# RP2350 register map
Vendor: Raspberry Pi; File version: 0.1
CPU: CM33 r1p0, little endian, MPU, FPU, VTOR, 4 interrupt priority bits, 54 interrupts, 8 SAU regions
Registers are 32-bit, read-write, reset 0x0 unless marked. A register's access mark holds for its fields unless they carry their own. Offsets are from the block's base; [hi:lo] are bit positions; {n}, {i} and the like mark numbered series; 'fields as' and 'values as' point back to an identical list; <NAME> marks a mode.

## OTP_DATA — Predefined OTP data layout for RP2350
Base 0x40130000
0x00 CHIPID_DEVICE0 ro — Lower 16 bits of test lot/device number (ECC)
  [15:0] CHIPID_DEVICE0
0x01 CHIPID_DEVICE1 ro — Upper 16 bits of test lot/device number (ECC)
  [15:0] CHIPID_DEVICE1
0x02 CHIPID_WAFER0 ro — Lower 16 bits of wafer lot (ECC)
  [15:0] CHIPID_WAFER0
0x03 CHIPID_WAFER1 ro — Upper 16 bits of wafer lot (ECC)
  [15:0] CHIPID_WAFER1
{0x4+i} RANDID{i} ro (i=0..7) — 16 bits of random data sampled from the TRNG during manufacturing (ECC)
  [15:0] RANDID{i}
0x10 ROSC_CALIB ro — Ring oscillator calibration constant measured during manufacturing (ECC)
  [15:0] ROSC_CALIB
0x11 LPOSC_CALIB ro — Low-power oscillator calibration constant measured during manufacturing (ECC)
  [15:0] LPOSC_CALIB
0x36 INFO_CRC0 ro — Lower 16 bits of CRC32 of OTP addresses 0x00 through 0x6b (polynomial 0x4c11db7, input reflected, output reflected, seed all-ones, final XOR all-ones) (ECC)
  [15:0] INFO_CRC0
0x37 INFO_CRC1 ro — Upper 16 bits of CRC32 of OTP addresses 0x00 through 0x6b (ECC)
  [15:0] INFO_CRC1
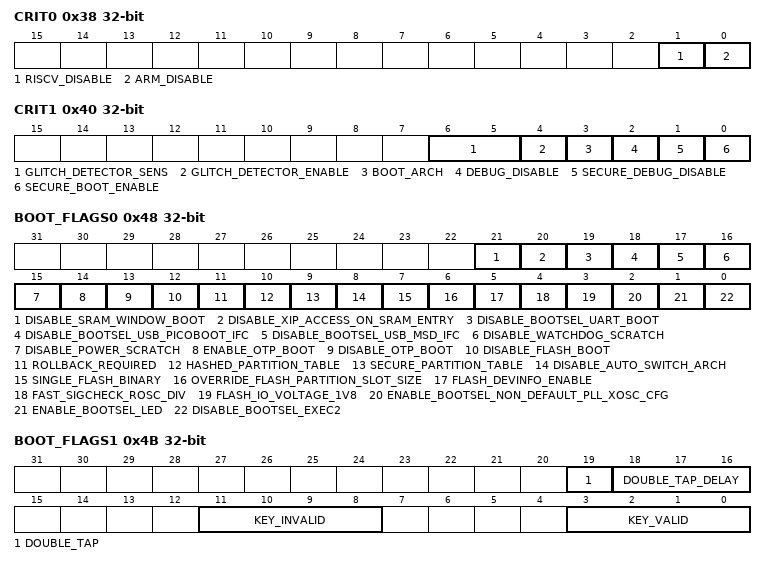
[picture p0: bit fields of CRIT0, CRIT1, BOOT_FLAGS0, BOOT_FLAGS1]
0x38 CRIT0 ro — Page 0 critical boot flags (RBIT-8)
  [1] RISCV_DISABLE — Permanently disable RISC-V processors (Hazard3)
  [0] ARM_DISABLE — Permanently disable ARM processors (Cortex-M33)
{0x38+i} CRIT0_R{i} ro (i=1..7) — Redundant copy of CRIT0
  [23:0] CRIT0_R{i}
0x40 CRIT1 ro — Page 1 critical boot flags (RBIT-8)
  [6:5] GLITCH_DETECTOR_SENS — Increase the sensitivity of the glitch detectors from their default.
  [4] GLITCH_DETECTOR_ENABLE — Arm the glitch detectors to reset the system if an abnormal clock/power event is observed.
  [3] BOOT_ARCH — Set the default boot architecture, 0=ARM 1=RISC-V. Ignored if ARM_DISABLE, RISCV_DISABLE or SECURE_BOOT_ENABLE is set.
  [2] DEBUG_DISABLE — Disable all debug access
  [1] SECURE_DEBUG_DISABLE — Disable Secure debug access
  [0] SECURE_BOOT_ENABLE — Enable boot signature enforcement, and permanently disable the RISC-V cores.
{0x40+i} CRIT1_R{i} ro (i=1..7) — Redundant copy of CRIT1
  [23:0] CRIT1_R{i}
0x48 BOOT_FLAGS0 ro — Disable/Enable boot paths/features in the RP2350 mask ROM. Disables always supersede enables. Enables are provided where there are other configurations in OTP that must be valid. (RBIT-3)
  [21] DISABLE_SRAM_WINDOW_BOOT
  [20] DISABLE_XIP_ACCESS_ON_SRAM_ENTRY
  [19] DISABLE_BOOTSEL_UART_BOOT
  [18] DISABLE_BOOTSEL_USB_PICOBOOT_IFC
  [17] DISABLE_BOOTSEL_USB_MSD_IFC
  [16] DISABLE_WATCHDOG_SCRATCH
  [15] DISABLE_POWER_SCRATCH
  [14] ENABLE_OTP_BOOT — Enable OTP boot. A number of OTP rows specified by OTPBOOT_LEN will be loaded, starting from OTPBOOT_SRC, into the SRAM location specified by OTPBOOT_DST1 and OTPBOOT_DST0. . The loaded program image is stored with ECC, 16 bits per row, and must contain a valid IMAGE_DEF. Do not set this bit without first programming an image into OTP and configuring OTPBOOT_LEN, OTPBOOT_SRC, OTPBOOT_DST0 and OTPBOOT_DST1. . Note that OTPBOOT_LEN and OTPBOOT_SRC must be even numbers of OTP rows. Equivalently, the image must be a multiple of 32 bits in size, and must start at a 32-bit-aligned address in the ECC read data address window.
  [13] DISABLE_OTP_BOOT — Takes precedence over ENABLE_OTP_BOOT.
  [12] DISABLE_FLASH_BOOT
  [11] ROLLBACK_REQUIRED — Require binaries to have a rollback version. Set automatically the first time a binary with a rollback version is booted.
  [10] HASHED_PARTITION_TABLE — Require a partition table to be hashed (if not signed)
  [9] SECURE_PARTITION_TABLE — Require a partition table to be signed
  [8] DISABLE_AUTO_SWITCH_ARCH — Disable auto-switch of CPU architecture on boot when the (only) binary to be booted is for the other Arm/RISC-V architecture and both architectures are enabled
  [7] SINGLE_FLASH_BINARY — Restrict flash boot path to use of a single binary at the start of flash
  [6] OVERRIDE_FLASH_PARTITION_SLOT_SIZE — Override the limit for default flash metadata scanning. . The value is specified in FLASH_PARTITION_SLOT_SIZE. Make sure FLASH_PARTITION_SLOT_SIZE is valid before setting this bit
  [5] FLASH_DEVINFO_ENABLE — Mark FLASH_DEVINFO as containing valid, ECC'd data which describes external flash devices.
  [4] FAST_SIGCHECK_ROSC_DIV — Enable quartering of ROSC divisor during signature check, to reduce secure boot time
  [3] FLASH_IO_VOLTAGE_1V8 — If 1, configure the QSPI pads for 1.8 V operation when accessing flash for the first time from the bootrom, using the VOLTAGE_SELECT register for the QSPI pads bank. This slightly improves the input timing of the pads at low voltages, but does not affect their output characteristics. . If 0, leave VOLTAGE_SELECT in its reset state (suitable for operation at and above 2.5 V)
  [2] ENABLE_BOOTSEL_NON_DEFAULT_PLL_XOSC_CFG — Enable loading of the non-default XOSC and PLL configuration before entering BOOTSEL mode. . Ensure that BOOTSEL_XOSC_CFG and BOOTSEL_PLL_CFG are correctly programmed before setting this bit. . If this bit is set, user software may use the contents of BOOTSEL_PLL_CFG to calculated the expected XOSC frequency based on the fixed USB boot frequency of 48 MHz.
  [1] ENABLE_BOOTSEL_LED — Enable bootloader activity LED. If set, bootsel_led_cfg is assumed to be valid
  [0] DISABLE_BOOTSEL_EXEC2
0x49 BOOT_FLAGS0_R1 ro — Redundant copy of BOOT_FLAGS0
  [23:0] BOOT_FLAGS0_R1
0x4A BOOT_FLAGS0_R2 ro — Redundant copy of BOOT_FLAGS0
  [23:0] BOOT_FLAGS0_R2
0x4B BOOT_FLAGS1 ro — Disable/Enable boot paths/features in the RP2350 mask ROM. Disables always supersede enables. Enables are provided where there are other configurations in OTP that must be valid. (RBIT-3)
  [19] DOUBLE_TAP — Enable entering BOOTSEL mode via double-tap of the RUN/RSTn pin. Adds a significant delay to boot time, as configured by DOUBLE_TAP_DELAY. . This functions by waiting at startup (i.e. following a reset) to see if a second reset is applied soon afterward. The second reset is detected by the bootrom with help of the POWMAN_CHIP_RESET_DOUBLE_TAP flag, which is not reset by the external reset pin, and the bootrom enters BOOTSEL mode (NSBOOT) to await further instruction over USB or UART.
  [18:16] DOUBLE_TAP_DELAY — Adjust how long to wait for a second reset when double tap BOOTSEL mode is enabled via DOUBLE_TAP. The minimum is 50 milliseconds, and each unit of this field adds an additional 50 milliseconds. . For example, settings this field to its maximum value of 7 will cause the chip to wait for 400 milliseconds at boot to check for a second reset which requests entry to BOOTSEL mode. . 200 milliseconds (DOUBLE_TAP_DELAY=3) is a good intermediate value.
  [11:8] KEY_INVALID — Mark a boot key as invalid, or prevent it from ever becoming valid. The bootrom will ignore any boot key marked as invalid during secure boot signature checks. . Each bit in this field corresponds to one of the four 256-bit boot key hashes that may be stored in page 2 of the OTP. . When provisioning boot keys, it's recommended to mark any boot key slots you don't intend to use as KEY_INVALID, so that spurious keys can not be installed at a later time.
  [3:0] KEY_VALID — Mark each of the possible boot keys as valid. The bootrom will check signatures against all valid boot keys, and ignore invalid boot keys. . Each bit in this field corresponds to one of the four 256-bit boot key hashes that may be stored in page 2 of the OTP. . A KEY_VALID bit is ignored if the corresponding KEY_INVALID bit is set. Boot keys are considered valid only when KEY_VALID is set and KEY_INVALID is clear. . Do not mark a boot key as KEY_VALID if it does not contain a valid SHA-256 hash of your secp256k1 public key. Verify keys after programming, before setting the KEY_VALID bits -- a boot key with uncorrectable ECC faults will render your device unbootable if secure boot is enabled. . Do not enable secure boot without first installing a valid key. This will render your device unbootable.
0x4C BOOT_FLAGS1_R1 ro — Redundant copy of BOOT_FLAGS1
  [23:0] BOOT_FLAGS1_R1
0x4D BOOT_FLAGS1_R2 ro — Redundant copy of BOOT_FLAGS1
  [23:0] BOOT_FLAGS1_R2
0x4E DEFAULT_BOOT_VERSION0 ro — Default boot version thermometer counter, bits 23:0 (RBIT-3)
  [23:0] DEFAULT_BOOT_VERSION0
0x4F DEFAULT_BOOT_VERSION0_R1 ro — Redundant copy of DEFAULT_BOOT_VERSION0
  [23:0] DEFAULT_BOOT_VERSION0_R1
0x50 DEFAULT_BOOT_VERSION0_R2 ro — Redundant copy of DEFAULT_BOOT_VERSION0
  [23:0] DEFAULT_BOOT_VERSION0_R2
0x51 DEFAULT_BOOT_VERSION1 ro — Default boot version thermometer counter, bits 47:24 (RBIT-3)
  [23:0] DEFAULT_BOOT_VERSION1
0x52 DEFAULT_BOOT_VERSION1_R1 ro — Redundant copy of DEFAULT_BOOT_VERSION1
  [23:0] DEFAULT_BOOT_VERSION1_R1
0x53 DEFAULT_BOOT_VERSION1_R2 ro — Redundant copy of DEFAULT_BOOT_VERSION1
  [23:0] DEFAULT_BOOT_VERSION1_R2
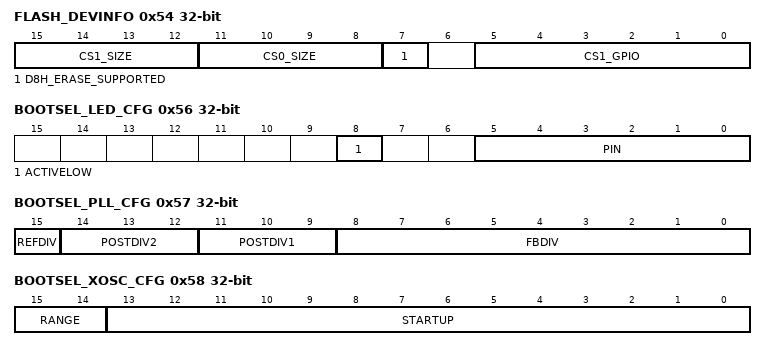
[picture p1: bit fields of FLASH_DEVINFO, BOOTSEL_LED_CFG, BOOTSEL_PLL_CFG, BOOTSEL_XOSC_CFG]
0x54 FLASH_DEVINFO ro — Stores information about external flash device(s). (ECC) . Assumed to be valid if BOOT_FLAGS0_FLASH_DEVINFO_ENABLE is set.
  [15:12] CS1_SIZE — The size of the flash/PSRAM device on chip select 1 (addressable at 0x11000000 through 0x11ffffff). . A value of zero is decoded as a size of zero (no device). Nonzero values are decoded as 4kiB << CS1_SIZE. For example, four megabytes is encoded with a CS1_SIZE value of 10, and 16 megabytes is encoded with a CS1_SIZE value of 12. . When BOOT_FLAGS0_FLASH_DEVINFO_ENABLE is not set, a default of zero is used.
    0=NONE; 1=8K; 2=16K; 3=32K; 4=64k; 5=128K; 6=256K; 7=512K; 8=1M; 9=2M; 10=4M; 11=8M; 12=16M
  [11:8] CS0_SIZE — The size of the flash/PSRAM device on chip select 0 (addressable at 0x10000000 through 0x10ffffff). . A value of zero is decoded as a size of zero (no device). Nonzero values are decoded as 4kiB << CS0_SIZE. For example, four megabytes is encoded with a CS0_SIZE value of 10, and 16 megabytes is encoded with a CS0_SIZE value of 12. . When BOOT_FLAGS0_FLASH_DEVINFO_ENABLE is not set, a default of 12 (16 MiB) is used.
    values as CS1_SIZE
  [7] D8H_ERASE_SUPPORTED — If true, all attached devices are assumed to support (or ignore, in the case of PSRAM) a block erase command with a command prefix of D8h, an erase size of 64 kiB, and a 24-bit address. Almost all 25-series flash devices support this command. . If set, the bootrom will use the D8h erase command where it is able, to accelerate bulk erase operations. This makes flash programming faster. . When BOOT_FLAGS0_FLASH_DEVINFO_ENABLE is not set, this field defaults to false.
  [5:0] CS1_GPIO — Indicate a GPIO number to be used for the secondary flash chip select (CS1), which selects the external QSPI device mapped at system addresses 0x11000000 through 0x11ffffff. There is no such configuration for CS0, as the primary chip select has a dedicated pin. . On RP2350 the permissible GPIO numbers are 0, 8, 19 and 47. . Ignored if CS1_size is zero. If CS1_SIZE is nonzero, the bootrom will automatically configure this GPIO as a second chip select upon entering the flash boot path, or entering any other path that may use the QSPI flash interface, such as BOOTSEL mode (nsboot).
0x55 FLASH_PARTITION_SLOT_SIZE ro — Gap between partition table slot 0 and slot 1 at the start of flash (the default size is 4096 bytes) (ECC) Enabled by the OVERRIDE_FLASH_PARTITION_SLOT_SIZE bit in BOOT_FLAGS, the size is 4096 * (value + 1)
  [15:0] FLASH_PARTITION_SLOT_SIZE
0x56 BOOTSEL_LED_CFG ro — Pin configuration for LED status, used by USB bootloader. (ECC). Must be valid if BOOT_FLAGS0_ENABLE_BOOTSEL_LED is set.
  [8] ACTIVELOW — LED is active-low. (Default: active-high.)
  [5:0] PIN — GPIO index to use for bootloader activity LED.
0x57 BOOTSEL_PLL_CFG ro — Optional PLL configuration for BOOTSEL mode. (ECC) . This should be configured to produce an exact 48 MHz based on the crystal oscillator frequency. User mode software may also use this value to calculate the expected crystal frequency based on an assumed 48 MHz PLL output. . If no configuration is given, the crystal is assumed to be 12 MHz. . The PLL frequency can be calculated as: . PLL out = (XOSC frequency / (REFDIV+1)) x FBDIV / (POSTDIV1 x POSTDIV2) . Conversely the crystal frequency can be calculated as: . XOSC frequency = 48 MHz x (REFDIV+1) x (POSTDIV1 x POSTDIV2) / FBDIV (Note the +1 on REFDIV is because the value stored in this OTP location is the actual divisor value minus one.) . Valid if and only if BOOTSEL_CFG_NONDEFAULT_CLOCK_CFG bit is set. That bit should be set only after this row and BOOTSEL_XOSC_CFG are both correctly programmed.
  [15] REFDIV — PLL reference divisor, minus one. . Programming a value of 0 means a reference divisor of 1. Programming a value of 1 means a reference divisor of 2 (for exceptionally fast XIN inputs)
  [14:12] POSTDIV2 — PLL post-divide 2 divisor, in the range 1..7 inclusive.
  [11:9] POSTDIV1 — PLL post-divide 1 divisor, in the range 1..7 inclusive.
  [8:0] FBDIV — PLL feedback divisor, in the range 16..320 inclusive.
0x58 BOOTSEL_XOSC_CFG ro — Non-default crystal oscillator configuration for the USB bootloader. (ECC) . These values may also be used by user code configuring the crystal oscillator. . Valid if and only if BOOTSEL_CFG_NONDEFAULT_CLOCK_CFG bit is set. That bit should be set only after this row and BOOTSEL_PLL_CFG are both correctly programmed.
  [15:14] RANGE — Value of the XOSC_CTRL_FREQ_RANGE register.
    0=1_15MHZ; 1=10_30MHZ; 2=25_60MHZ; 3=40_100MHZ
  [13:0] STARTUP — Value of the XOSC_STARTUP register
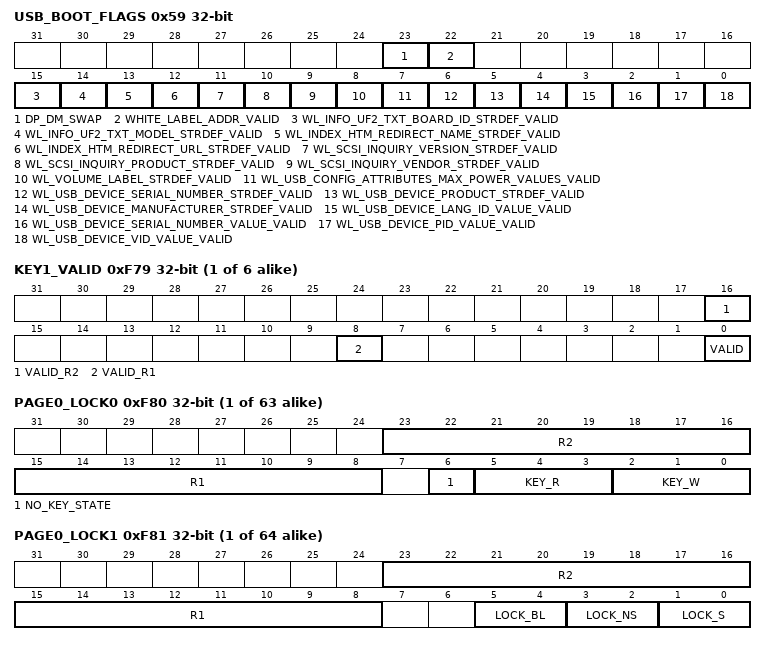
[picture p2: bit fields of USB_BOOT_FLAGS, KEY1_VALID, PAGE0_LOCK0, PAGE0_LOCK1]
0x59 USB_BOOT_FLAGS ro — USB boot specific feature flags (RBIT-3)
  [23] DP_DM_SWAP — Swap DM/DP during USB boot, to support board layouts with mirrored USB routing (deliberate or accidental).
  [22] WHITE_LABEL_ADDR_VALID — valid flag for INFO_UF2_TXT_BOARD_ID_STRDEF entry of the USB_WHITE_LABEL struct (index 15)
  [15] WL_INFO_UF2_TXT_BOARD_ID_STRDEF_VALID — valid flag for the USB_WHITE_LABEL_ADDR field
  [14] WL_INFO_UF2_TXT_MODEL_STRDEF_VALID — valid flag for INFO_UF2_TXT_MODEL_STRDEF entry of the USB_WHITE_LABEL struct (index 14)
  [13] WL_INDEX_HTM_REDIRECT_NAME_STRDEF_VALID — valid flag for INDEX_HTM_REDIRECT_NAME_STRDEF entry of the USB_WHITE_LABEL struct (index 13)
  [12] WL_INDEX_HTM_REDIRECT_URL_STRDEF_VALID — valid flag for INDEX_HTM_REDIRECT_URL_STRDEF entry of the USB_WHITE_LABEL struct (index 12)
  [11] WL_SCSI_INQUIRY_VERSION_STRDEF_VALID — valid flag for SCSI_INQUIRY_VERSION_STRDEF entry of the USB_WHITE_LABEL struct (index 11)
  [10] WL_SCSI_INQUIRY_PRODUCT_STRDEF_VALID — valid flag for SCSI_INQUIRY_PRODUCT_STRDEF entry of the USB_WHITE_LABEL struct (index 10)
  [9] WL_SCSI_INQUIRY_VENDOR_STRDEF_VALID — valid flag for SCSI_INQUIRY_VENDOR_STRDEF entry of the USB_WHITE_LABEL struct (index 9)
  [8] WL_VOLUME_LABEL_STRDEF_VALID — valid flag for VOLUME_LABEL_STRDEF entry of the USB_WHITE_LABEL struct (index 8)
  [7] WL_USB_CONFIG_ATTRIBUTES_MAX_POWER_VALUES_VALID — valid flag for USB_CONFIG_ATTRIBUTES_MAX_POWER_VALUES entry of the USB_WHITE_LABEL struct (index 7)
  [6] WL_USB_DEVICE_SERIAL_NUMBER_STRDEF_VALID — valid flag for USB_DEVICE_SERIAL_NUMBER_STRDEF entry of the USB_WHITE_LABEL struct (index 6)
  [5] WL_USB_DEVICE_PRODUCT_STRDEF_VALID — valid flag for USB_DEVICE_PRODUCT_STRDEF entry of the USB_WHITE_LABEL struct (index 5)
  [4] WL_USB_DEVICE_MANUFACTURER_STRDEF_VALID — valid flag for USB_DEVICE_MANUFACTURER_STRDEF entry of the USB_WHITE_LABEL struct (index 4)
  [3] WL_USB_DEVICE_LANG_ID_VALUE_VALID — valid flag for USB_DEVICE_LANG_ID_VALUE entry of the USB_WHITE_LABEL struct (index 3)
  [2] WL_USB_DEVICE_SERIAL_NUMBER_VALUE_VALID — valid flag for USB_DEVICE_BCD_DEVICEVALUE entry of the USB_WHITE_LABEL struct (index 2)
  [1] WL_USB_DEVICE_PID_VALUE_VALID — valid flag for USB_DEVICE_PID_VALUE entry of the USB_WHITE_LABEL struct (index 1)
  [0] WL_USB_DEVICE_VID_VALUE_VALID — valid flag for USB_DEVICE_VID_VALUE entry of the USB_WHITE_LABEL struct (index 0)
0x5A USB_BOOT_FLAGS_R1 ro — Redundant copy of USB_BOOT_FLAGS
  [23:0] USB_BOOT_FLAGS_R1
0x5B USB_BOOT_FLAGS_R2 ro — Redundant copy of USB_BOOT_FLAGS
  [23:0] USB_BOOT_FLAGS_R2
0x5C USB_WHITE_LABEL_ADDR ro — Row index of the USB_WHITE_LABEL structure within OTP (ECC) . The table has 16 rows, each of which are also ECC and marked valid by the corresponding valid bit in USB_BOOT_FLAGS (ECC). . The entries are either _VALUEs where the 16 bit value is used as is, or _STRDEFs which acts as a pointers to a string value. . The value stored in a _STRDEF is two separate bytes: The low seven bits of the first (LSB) byte indicates the number of characters in the string, and the top bit of the first (LSB) byte if set to indicate that each character in the string is two bytes (Unicode) versus one byte if unset. The second (MSB) byte represents the location of the string data, and is encoded as the number of rows from this USB_WHITE_LABEL_ADDR; i.e. the row of the start of the string is USB_WHITE_LABEL_ADDR value + msb_byte. . In each case, the corresponding valid bit enables replacing the default value for the corresponding item provided by the boot rom. . Note that Unicode _STRDEFs are only supported for USB_DEVICE_PRODUCT_STRDEF, USB_DEVICE_SERIAL_NUMBER_STRDEF and USB_DEVICE_MANUFACTURER_STRDEF. Unicode values will be ignored if specified for other fields, and non-unicode values for these three items will be converted to Unicode characters by setting the upper 8 bits to zero. . Note that if the USB_WHITE_LABEL structure or the corresponding strings are not readable by BOOTSEL mode based on OTP permissions, or if alignment requirements are not met, then the corresponding default values are used. . The index values indicate where each field is located (row USB_WHITE_LABEL_ADDR value + index):
  [15:0] USB_WHITE_LABEL_ADDR
    0=INDEX_USB_DEVICE_VID_VALUE; 1=INDEX_USB_DEVICE_PID_VALUE; 2=INDEX_USB_DEVICE_BCD_DEVICE_VALUE; 3=INDEX_USB_DEVICE_LANG_ID_VALUE; 4=INDEX_USB_DEVICE_MANUFACTURER_STRDEF; 5=INDEX_USB_DEVICE_PRODUCT_STRDEF; 6=INDEX_USB_DEVICE_SERIAL_NUMBER_STRDEF; 7=INDEX_USB_CONFIG_ATTRIBUTES_MAX_POWER_VALUES; 8=INDEX_VOLUME_LABEL_STRDEF; 9=INDEX_SCSI_INQUIRY_VENDOR_STRDEF; 10=INDEX_SCSI_INQUIRY_PRODUCT_STRDEF; 11=INDEX_SCSI_INQUIRY_VERSION_STRDEF; 12=INDEX_INDEX_HTM_REDIRECT_URL_STRDEF; 13=INDEX_INDEX_HTM_REDIRECT_NAME_STRDEF; 14=INDEX_INFO_UF2_TXT_MODEL_STRDEF; 15=INDEX_INFO_UF2_TXT_BOARD_ID_STRDEF
0x5E OTPBOOT_SRC ro — OTP start row for the OTP boot image. (ECC) . If OTP boot is enabled, the bootrom will load from this location into SRAM and then directly enter the loaded image. Note that the image must be signed if SECURE_BOOT_ENABLE is set. The image itself is assumed to be ECC-protected. . This must be an even number. Equivalently, the OTP boot image must start at a word-aligned location in the ECC read data address window.
  [15:0] OTPBOOT_SRC
0x5F OTPBOOT_LEN ro — Length in rows of the OTP boot image. (ECC) . OTPBOOT_LEN must be even. The total image size must be a multiple of 4 bytes (32 bits).
  [15:0] OTPBOOT_LEN
0x60 OTPBOOT_DST0 ro — Bits 15:0 of the OTP boot image load destination (and entry point). (ECC) . This must be a location in main SRAM (main SRAM is addresses 0x20000000 through 0x20082000) and must be word-aligned.
  [15:0] OTPBOOT_DST0
0x61 OTPBOOT_DST1 ro — Bits 31:16 of the OTP boot image load destination (and entry point). (ECC) . This must be a location in main SRAM (main SRAM is addresses 0x20000000 through 0x20082000) and must be word-aligned.
  [15:0] OTPBOOT_DST1
{0x80+i} BOOTKEY0_{i} ro (i=0..15) — Bits {16i+15}:{16i} of SHA-256 hash of boot key 0 (ECC)
  [15:0] BOOTKEY0_{i}
{0x90+i} BOOTKEY1_{i} ro (i=0..15) — Bits {16i+15}:{16i} of SHA-256 hash of boot key 1 (ECC)
  [15:0] BOOTKEY1_{i}
{0xA0+i} BOOTKEY2_{i} ro (i=0..15) — Bits {16i+15}:{16i} of SHA-256 hash of boot key 2 (ECC)
  [15:0] BOOTKEY2_{i}
{0xB0+i} BOOTKEY3_{i} ro (i=0..15) — Bits {16i+15}:{16i} of SHA-256 hash of boot key 3 (ECC)
  [15:0] BOOTKEY3_{i}
{0xF48+i} KEY1_{i} ro (i=0..7) — Bits {16i+15}:{16i} of OTP access key 1 (ECC)
  [15:0] KEY1_{i}
{0xF50+i} KEY2_{i} ro (i=0..7) — Bits {16i+15}:{16i} of OTP access key 2 (ECC)
  [15:0] KEY2_{i}
{0xF58+i} KEY3_{i} ro (i=0..7) — Bits {16i+15}:{16i} of OTP access key 3 (ECC)
  [15:0] KEY3_{i}
{0xF60+i} KEY4_{i} ro (i=0..7) — Bits {16i+15}:{16i} of OTP access key 4 (ECC)
  [15:0] KEY4_{i}
{0xF68+i} KEY5_{i} ro (i=0..7) — Bits {16i+15}:{16i} of OTP access key 5 (ECC)
  [15:0] KEY5_{i}
{0xF70+i} KEY6_{i} ro (i=0..7) — Bits {16i+15}:{16i} of OTP access key 6 (ECC)
  [15:0] KEY6_{i}
{0xF78+i} KEY{i}_VALID ro (i=1..6) — Valid flag for key {i}. Once the valid flag is set, the key can no longer be read or written, and becomes a valid fixed key for protecting OTP pages.
  [16] VALID_R2 — Redundant copy of VALID, with 3-way majority vote
  [8] VALID_R1 — Redundant copy of VALID, with 3-way majority vote
  [0] VALID
{0xF80+2i} PAGE{i}_LOCK0 ro (i=0..62) — Lock configuration LSBs for page {i} (rows {0x0+0x40*i} through {0x3F+0x40*i}). Locks are stored with 3-way majority vote encoding, so that bits can be set independently. . This OTP location is always readable, and is write-protected by its own permissions.
  [23:16] R2 — Redundant copy of bits 7:0
  [15:8] R1 — Redundant copy of bits 7:0
  [6] NO_KEY_STATE — State when at least one key is registered for this page and no matching key has been entered.
    0=read_only; 1=inaccessible
  [5:3] KEY_R — Index 1-6 of a hardware key which must be entered to grant read access, or 0 if no such key is required.
  [2:0] KEY_W — Index 1-6 of a hardware key which must be entered to grant write access, or 0 if no such key is required.
{0xF81+2i} PAGE{i}_LOCK1 ro (i=0..63) — Lock configuration MSBs for page {i} (rows {0x0+0x40*i} through {0x3F+0x40*i}). Locks are stored with 3-way majority vote encoding, so that bits can be set independently. . This OTP location is always readable, and is write-protected by its own permissions.
  [23:16] R2 — Redundant copy of bits 7:0
  [15:8] R1 — Redundant copy of bits 7:0
  [5:4] LOCK_BL — Dummy lock bits reserved for bootloaders (including the RP2350 USB bootloader) to store their own OTP access permissions. No hardware effect, and no corresponding SW_LOCKx registers.
    0=read_write (Bootloader permits user reads and writes to this page); 1=read_only (Bootloader permits user reads of this page); 2=reserved (Do not use. Behaves the same as INACCESSIBLE); 3=inaccessible (Bootloader does not permit user access to this page)
  [3:2] LOCK_NS — Lock state for NonSecure accesses to this page. Thermometer-coded, so lock state can be advanced permanently from any state to any less-permissive state by programming OTP. Software can also advance the lock state temporarily (until next OTP reset) using the SW_LOCKx registers. . Note that READ_WRITE and READ_ONLY are equivalent in hardware, as the SBPI programming interface is not accessible to NonSecure software. However, Secure software may check these bits to apply write permissions to a NonSecure OTP programming API.
    0=read_write (Page can be read by NonSecure software, and Secure software may permit NonSecure writes.); 1=read_only (Page can be read by NonSecure software); 2=reserved (Do not use. Behaves the same as INACCESSIBLE.); 3=inaccessible (Page can not be accessed by NonSecure software.)
  [1:0] LOCK_S — Lock state for Secure accesses to this page. Thermometer-coded, so lock state can be advanced permanently from any state to any less-permissive state by programming OTP. Software can also advance the lock state temporarily (until next OTP reset) using the SW_LOCKx registers.
    0=read_write (Page is fully accessible by Secure software.); 1=read_only (Page can be read by Secure software, but can not be written.); 2=reserved (Do not use. Behaves the same as INACCESSIBLE.); 3=inaccessible (Page can not be accessed by Secure software.)
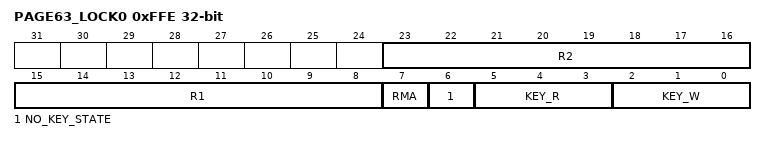
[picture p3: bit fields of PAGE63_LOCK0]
0xFFE PAGE63_LOCK0 ro — Lock configuration LSBs for page 63 (rows 0xfc0 through 0xfff). Locks are stored with 3-way majority vote encoding, so that bits can be set independently. . This OTP location is always readable, and is write-protected by its own permissions.
  [23:16] R2 — Redundant copy of bits 7:0
  [15:8] R1 — Redundant copy of bits 7:0
  [7] RMA — Decommission for RMA of a suspected faulty device. This re-enables the factory test JTAG interface, and makes pages 3 through 61 of the OTP permanently inaccessible.
  [6] NO_KEY_STATE — State when at least one key is registered for this page and no matching key has been entered.
    0=read_only; 1=inaccessible
  [5:3] KEY_R — Index 1-6 of a hardware key which must be entered to grant read access, or 0 if no such key is required.
  [2:0] KEY_W — Index 1-6 of a hardware key which must be entered to grant write access, or 0 if no such key is required.
